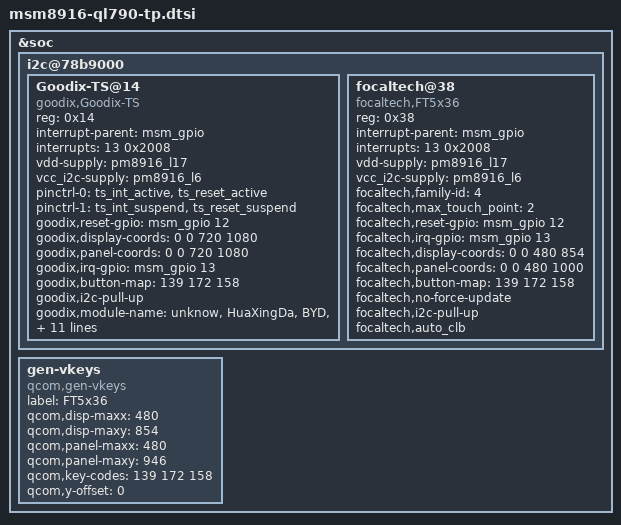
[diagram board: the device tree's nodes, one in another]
/* Copyright (c) 2013, The Linux Foundation. All rights reserved.
 *
 * This program is free software; you can redistribute it and/or modify
 * it under the terms of the GNU General Public License version 2 and
 * only version 2 as published by the Free Software Foundation.
 *
 * This program is distributed in the hope that it will be useful,
 * but WITHOUT ANY WARRANTY; without even the implied warranty of
 * MERCHANTABILITY or FITNESS FOR A PARTICULAR PURPOSE.  See the
 * GNU General Public License for more details.
 */

/*
 * As a general rule, only version-specific property overrides should be placed
 * inside this file. However, device definitions should be placed inside the
 * yep_product_ql1001_flatform.dtsi file.
 */

/*
     Date            Author         	 Why
   2014-07-29      aidongdong          add 1008 yusun product
   2014-08-11      zengguang          add pinctrl
   2014-08-18      chenchen           add module name for yusun
   2014-10-16      pangle             add hall mod send cfg function


    Date    		Author   		Module   	 	Sensor_id    Old_ver    New_ver
  2014.08.11	zengguang	huaxingda		1 				  0x41
  2014.08.18   chenchen   huaxingda         1         0x41        0x42
  2014.09.15   chenchen   huaxingda         1         0x42        0x43
  2014.10.09   chenchen   huaxingda         1         0x43        0x44
  2014.10.16   pangle     huaxingda         1         0x43        0x44
  2014.10.21   pangle     huaxingda hall cfg         1         0x44        0x45
  2014.10.22   pangle     huaxingda hall cfg         1         0x45        0x46
  2014.10.31   pangle     huaxingda hall cfg         1         0x46        0x47
  2014.11.03   pangle     huaxingda        					 1         0x43        0x48
  2014.11.03   pangle     huaxingda hall cfg         1         0x47        0x48
  2014.11.27   zengguang     BYD 		          1         NULL        0x41
  2014.12.03   zengguang     BYD 		          1         0x41        0x43
  2014.12.03   zengguang     BYD hall		          1         NULL        0x43
*/

&soc {
	i2c@78b9000 { /* BLSP1 QUP5 */
	Goodix-TS@14 {
		compatible = "goodix,Goodix-TS";
		reg = <0x14>;
		interrupt-parent = <&msm_gpio>;
		interrupts = <13 0x2008>;
		vdd-supply = <&pm8916_l17>;
		vcc_i2c-supply = <&pm8916_l6>;
		pinctrl-names = "pmx_ts_active","pmx_ts_suspend";
		pinctrl-0 = <&ts_int_active &ts_reset_active>;
		pinctrl-1 = <&ts_int_suspend &ts_reset_suspend>;
		goodix,reset-gpio = <&msm_gpio 12 0x00>;
		goodix,display-coords = <0 0 720 1080>;
		goodix,panel-coords = <0 0 720 1080>;
		goodix,irq-gpio = <&msm_gpio 13 0x00>;
		goodix,button-map = <139 172 158>;
		goodix,i2c-pull-up;
		goodix,module-name = "unknow","HuaXingDa","BYD","unknow","unknow","unknow";
		/*gt915,shenyue  20150428 wangkai*/
		goodix,cfg-data0 = [
			41 D0 02 00 05 0A 35 00 01 08
			28 05 50 32 03 05 00 00 00 00
			00 00 00 17 19 1C 14 8B 2B 0C
			30 32 31 0D 00 00 00 22 03 1D
			00 00 00 00 00 00 00 32 00 00
			00 1E 50 94 C5 02 07 00 00 04
			AD 21 00 94 28 00 7D 31 00 6D
			3B 00 60 48 00 60 00 00 00 00
			00 00 00 00 00 00 00 00 00 00
			00 00 00 00 00 00 00 00 00 00
			00 00 00 00 00 00 00 00 00 00
			00 00 02 04 06 08 12 0E 18 16
			14 10 0C 0A FF FF 00 00 00 00
			00 00 00 00 00 00 00 00 00 00
			00 00 00 02 04 06 08 0A 0C 0F
			10 12 13 26 24 22 21 20 1F 1E
			1D 1C 18 16 FF FF FF FF 00 00
			00 00 00 00 00 00 00 00 00 00
			00 00 00 00 A2 01];
		/*gt915L,dijing module panel*/
		goodix,cfg-data1 = [
			43 D0 02 00 05 0A 05 00 01 08
			19 0A 50 32 03 F5 00 00 FF 7F
			00 00 00 00 00 00 00 8A 2B 0C
			32 34 D3 07 00 00 00 01 33 1D
			00 01 00 00 00 00 00 00 00 00
			29 1E 46 94 C5 02 07 00 1E 04
			BF 20 00 A3 26 00 8C 2D 00 77
			36 00 66 40 00 66 00 00 00 00
			00 00 00 00 00 00 00 00 00 00
			00 00 00 00 00 00 00 00 00 00
			00 00 00 00 00 00 0A 0F 06 00
			4B 32 02 04 06 08 0A 0C 0E 10
			12 14 16 18 FF FF 00 00 00 00
			00 00 00 00 00 00 00 00 00 00
			00 00 12 10 0F 0C 0A 08 06 04
			02 00 16 18 1C 1D 1E 1F 20 21
			22 24 26 FF FF FF FF FF 00 00
			00 00 00 00 00 00 00 00 00 00
			00 00 00 00 58 01];
		/*gt915L,BYD module panel*/
		goodix,cfg-data2 = [
			43 D0 02 00 05 0A 35 01 01 0A
			28 0A 50 32 03 05 00 00 FF 7F
			00 00 06 18 1A 1E 14 8C 2D 0D
			36 38 B5 06 00 0A 00 02 33 1D
			00 00 00 00 00 00 00 32 00 00
			23 2D 57 94 C5 02 07 00 00 04
			8E 30 00 7F 36 00 71 3E 00 64
			47 00 59 51 00 59 18 38 58 00
			F0 4A 3A DD DD 27 00 00 00 00
			00 00 00 00 00 00 00 00 00 00
			00 00 00 00 00 00 00 0F 00 00
			46 2D 1A 18 16 14 12 10 0E 0C
			0A 08 06 04 02 FF 00 00 00 00
			00 00 00 00 00 FF FF FF FF 0F
			FF 00 14 13 12 10 0F 0C 0A 08
			06 04 02 00 16 18 1C 1D 1E 1F
			20 21 22 24 26 28 29 FF FF 00
			00 FF FF FF FF FF FF FF FF FF
			FF FF FF FF 4A 01];
		/*gt9157,huaxingda hall module panel*/
		goodix,cfg-data7 = [
			4A D0 02 00 05 0A 35 01 01 08
			28 0F 4B 32 03 05 00 00 FF 7F
			00 00 0A 18 1A 1D 14 8A 2A 0B
			32 34 0C 08 03 14 00 05 33 1D
			00 01 00 00 00 00 00 00 00 00
			2D 1E 5A 94 C5 02 00 00 00 04
			AE 21 00 91 29 00 78 34 00 65
			41 00 57 51 00 57 18 30 48 00
			F0 4A 3A FF FF 27 00 00 00 00
			00 00 00 00 00 00 00 00 00 0F
			14 03 04 10 42 C8 0F 05 00 00
			3C 2D 16 14 12 10 0E 0C 0A 08
			06 04 02 FF FF FF 00 00 00 00
			00 00 00 00 00 00 00 14 00 00
			FF 00 13 12 10 0F 0A 08 06 04
			02 00 16 18 1C 1D 1E 1F 20 21
			22 24 FF FF FF FF FF FF 00 00
			00 FF FF FF FF FF FF FF FF FF
			FF FF FF FF 73 01];
		/*gt9157,BYD hall module panel*/
		goodix,cfg-data8 = [
			43 D0 02 00 05 0A 35 01 01 0A
			28 0A 50 32 03 05 00 00 FF 7F
			00 00 06 18 1A 1E 14 8C 2D 0D
			36 38 B5 06 00 0A 00 04 33 1D
			00 00 00 00 00 00 00 32 00 00
			1D 2D 57 94 C5 02 07 00 00 04
			8E 30 00 7F 36 00 71 3E 00 64
			47 00 59 51 00 59 18 38 58 00
			F0 4A 3A DD DD 27 00 00 00 00
			00 00 00 00 00 00 00 00 00 00
			00 00 00 00 00 00 00 14 00 00
			32 26 1A 18 16 14 12 10 0E 0C
			0A 08 06 04 02 FF 00 00 00 00
			00 00 00 00 00 FF FF FF FF 0F
			FF 00 14 13 12 10 0F 0C 0A 08
			06 04 02 00 16 18 1C 1D 1E 1F
			20 21 22 24 26 28 29 FF FF 00
			00 FF FF FF FF FF FF FF FF FF
			FF FF FF FF 64 01];
		};
		focaltech@38 {
			compatible = "focaltech,FT5x36";
			reg = <0x38>;
			interrupt-parent = <&msm_gpio>;
			interrupts = <13 0x2008>;
			vdd-supply = <&pm8916_l17>;
			vcc_i2c-supply = <&pm8916_l6>;
			focaltech,family-id = <4>;
			focaltech,max_touch_point = <2>;
			focaltech,reset-gpio = <&msm_gpio 12 0x00>;
			focaltech,irq-gpio = <&msm_gpio 13 0x00>;
			focaltech,display-coords = <0 0 480 854>;
			focaltech,panel-coords = <0 0 480 1000>;
			focaltech,button-map= <139 172 158>;
			focaltech,no-force-update;
			focaltech,i2c-pull-up;
			focaltech,auto_clb;
		};
	};
	gen-vkeys {
		compatible = "qcom,gen-vkeys";
		label = "FT5x36";
		qcom,disp-maxx = <480>;
		qcom,disp-maxy = <854>;
		qcom,panel-maxx = <480>;
		qcom,panel-maxy = <946>;
		qcom,key-codes = <139 172 158>;
		qcom,y-offset = <0>;
	};
};
